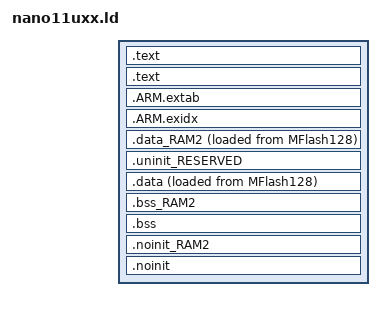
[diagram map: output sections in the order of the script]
/*
 * GENERATED FILE - DO NOT EDIT
 * (c) Code Red Technologies Ltd, 2008-2013
 * (c) NXP Semiconductors 2013-2013
 * Generated linker script file for LPC11U37/401
 * Created from generic_cpp.ld (LPCXpresso v6.0 (2 [Build 151] [2013-09-18] ))
 * By LPCXpresso v6.0.2 [Build 151] [2013-09-18]  on Tue Dec 10 14:12:35 CST 2013
 */


INCLUDE "nano11uxx_lib.ld"
INCLUDE "nano11uxx_mem.ld"

ENTRY(ResetISR)

SECTIONS
{

    /* MAIN TEXT SECTION */    
    .text : ALIGN(4)
    {
        FILL(0xff)
        __vectors_start__ = ABSOLUTE(.) ;
        KEEP(*(.isr_vector))
        
        /* Global Section Table */
        . = ALIGN(4) ;
        __section_table_start = .;
        __data_section_table = .;
        LONG(LOADADDR(.data));
        LONG(    ADDR(.data)) ;
        LONG(  SIZEOF(.data));
        LONG(LOADADDR(.data_RAM2));
        LONG(    ADDR(.data_RAM2)) ;
        LONG(  SIZEOF(.data_RAM2));
        __data_section_table_end = .;
        __bss_section_table = .;
        LONG(    ADDR(.bss));
        LONG(  SIZEOF(.bss));
        LONG(    ADDR(.bss_RAM2));
        LONG(  SIZEOF(.bss_RAM2));
        __bss_section_table_end = .;
        __section_table_end = . ;
        /* End of Global Section Table */
        

        *(.after_vectors*)
        
    } >MFlash128
    
    .text : ALIGN(4)    
    {
         *(.text*)
        *(.rodata .rodata.*)
        . = ALIGN(4);
        
        /* C++ constructors etc */
        . = ALIGN(4);
        KEEP(*(.init))
        
        . = ALIGN(4);
        __preinit_array_start = .;
        KEEP (*(.preinit_array))
        __preinit_array_end = .;
        
        . = ALIGN(4);
        __init_array_start = .;
        KEEP (*(SORT(.init_array.*)))
        KEEP (*(.init_array))
        __init_array_end = .;
        
        KEEP(*(.fini));
        
        . = ALIGN(4);
        KEEP (*crtbegin.o(.ctors))
        KEEP (*(EXCLUDE_FILE (*crtend.o) .ctors))
        KEEP (*(SORT(.ctors.*)))
        KEEP (*crtend.o(.ctors))
        
        . = ALIGN(4);
        KEEP (*crtbegin.o(.dtors))
        KEEP (*(EXCLUDE_FILE (*crtend.o) .dtors))
        KEEP (*(SORT(.dtors.*)))
        KEEP (*crtend.o(.dtors))
        /* End C++ */
    } > MFlash128

    /*
     * for exception handling/unwind - some Newlib functions (in common
     * with C++ and STDC++) use this. 
     */
    .ARM.extab : ALIGN(4)
    {
    	*(.ARM.extab* .gnu.linkonce.armextab.*)
    } > MFlash128
    __exidx_start = .;
    
    .ARM.exidx : ALIGN(4)
    {
    	*(.ARM.exidx* .gnu.linkonce.armexidx.*)
    } > MFlash128
    __exidx_end = .;
    
    _etext = .;
        
    
    /* DATA section for RamUsb2 */
    .data_RAM2 : ALIGN(4)
    {
       FILL(0xff)
    	*(.data.$RAM2*)
    	*(.data.$RamUsb2*)
       . = ALIGN(4) ;
    } > RamUsb2 AT>MFlash128
    
    /* MAIN DATA SECTION */
    

    .uninit_RESERVED : ALIGN(4)
    {
        KEEP(*(.bss.$RESERVED*))
        . = ALIGN(4) ;
        _end_uninit_RESERVED = .;
    } > RamLoc8

	
	/* Main DATA section (RamLoc8) */
	.data : ALIGN(4)
	{
	   FILL(0xff)
	   _data = . ;
	   *(vtable)
	   *(.data*)
	   . = ALIGN(4) ;
	   _edata = . ;
	} > RamLoc8 AT>MFlash128

    /* BSS section for RamUsb2 */
    .bss_RAM2 : ALIGN(4)
    {
    	*(.bss.$RAM2*)
    	*(.bss.$RamUsb2*)
       . = ALIGN(4) ;
    } > RamUsb2

    /* MAIN BSS SECTION */
    .bss : ALIGN(4)
    {
        _bss = .;
        *(.bss*)
        *(COMMON)
        . = ALIGN(4) ;
        _ebss = .;
        PROVIDE(end = .);
    } > RamLoc8
        
    /* NOINIT section for RamUsb2 */
    .noinit_RAM2 (NOLOAD) : ALIGN(4)
    {
    	*(.noinit.$RAM2*)
    	*(.noinit.$RamUsb2*)
       . = ALIGN(4) ;
    } > RamUsb2 
    
    /* DEFAULT NOINIT SECTION */
    .noinit (NOLOAD): ALIGN(4)
    {
        _noinit = .;
        *(.noinit*) 
         . = ALIGN(4) ;
        _end_noinit = .;
    } > RamLoc8
    
    PROVIDE(_pvHeapStart = .);
    PROVIDE(_vStackTop = __top_RamLoc8 - 0);
}
